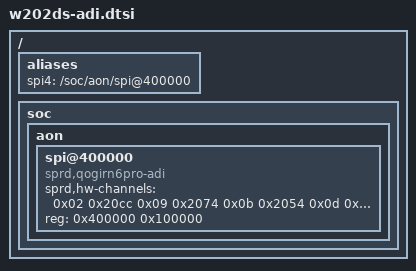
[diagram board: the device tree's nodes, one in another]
// W202DS Server hardware layout; split from the validated imported tree.
/ {
	aliases {
		spi4 = "/soc/aon/spi@400000";
	};
	soc {
		aon {
			spi@400000 {
				sprd,hw-channels = <0x02 0x20cc 0x09 0x2074 0x0b 0x2054 0x0d 0xa180 0x0f 0xa054 0x11 0xa1a0 0x13 0xa044 0x15 0xa0e8 0x17 0x244c 0x19 0xa074 0x1b 0x2044 0x1e 0x2020 0x20 0x217c 0x21 0x2188 0x22 0x21b8 0x23 0x21ac>;
				compatible = "sprd,qogirn6pro-adi";
				reg = <0x400000 0x100000>;
				#address-cells = <0x01>;
				#size-cells = <0x00>;
				phandle = <0x17f>;
			};
		};
	};
	__symbols__ {
		adi_bus = "/soc/aon/spi@400000";
	};
};
